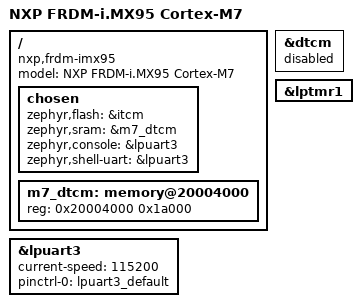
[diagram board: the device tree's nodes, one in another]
/*
 * SPDX-FileCopyrightText: Copyright The Zephyr Project Contributors
 * SPDX-License-Identifier: Apache-2.0
 */

/dts-v1/;

#include <nxp/imx/nxp_imx95_m7.dtsi>
#include "frdm_imx95-pinctrl.dtsi"

/ {
	compatible = "nxp,frdm-imx95";
	model = "NXP FRDM-i.MX95 Cortex-M7";

	chosen {
		zephyr,flash = &itcm;
		zephyr,sram = &m7_dtcm;
		zephyr,console = &lpuart3;
		zephyr,shell-uart = &lpuart3;
	};

	/* Leave suspend, non-cacheable and resource-table memory to firmware. */
	m7_dtcm: memory@20004000 {
		reg = <0x20004000 0x1a000>;
		device_type = "memory";
	};
};

/* Allocate through the bounded SRAM window, including explicit DTCM sections. */
&dtcm {
	status = "disabled";
};

&lpuart3 {
	current-speed = <115200>;
	pinctrl-0 = <&lpuart3_default>;
	pinctrl-names = "default";
	status = "okay";
};

&lptmr1 {
	status = "okay";
};
